# STM32L100C6U6 register map
File version: 1.0
Registers are 32-bit, access not given, reset 0x0 unless marked. A register's access mark holds for its fields unless they carry their own. Offsets are from the block's base; [hi:lo] are bit positions; {n}, {i} and the like mark numbered series.

## I2C1
Base 0x40005400
Same registers: I2C2 0x40005800
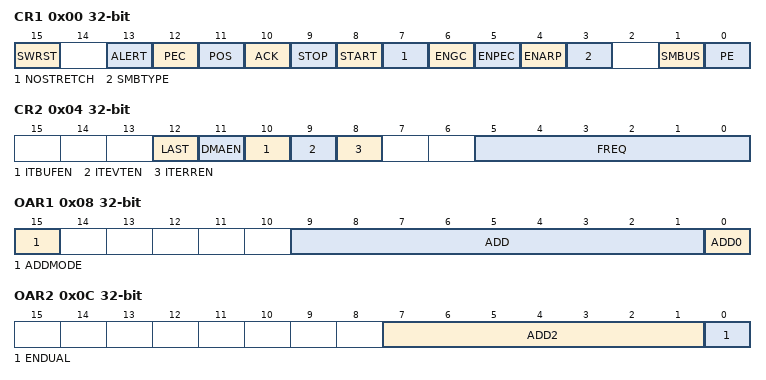
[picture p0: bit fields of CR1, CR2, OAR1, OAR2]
0x00 CR1
  [15] SWRST, [13] ALERT, [12] PEC, [11] POS, [10] ACK, [9] STOP, [8] START, [7] NOSTRETCH, [6] ENGC, [5] ENPEC, [4] ENARP, [3] SMBTYPE, [1] SMBUS, [0] PE
0x04 CR2
  [12] LAST, [11] DMAEN, [10] ITBUFEN, [9] ITEVTEN, [8] ITERREN, [5:0] FREQ
0x08 OAR1
  [15] ADDMODE, [9:1] ADD, [0] ADD0
0x0C OAR2
  [7:1] ADD2, [0] ENDUAL
0x10 DR
  [7:0] DR
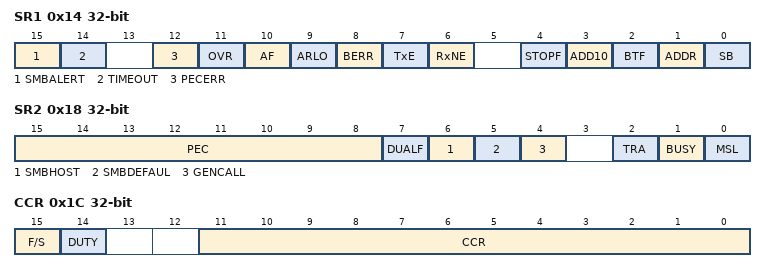
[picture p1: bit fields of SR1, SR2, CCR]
0x14 SR1
  [15] SMBALERT, [14] TIMEOUT, [12] PECERR, [11] OVR, [10] AF, [9] ARLO, [8] BERR, [7] TxE, [6] RxNE, [4] STOPF, [3] ADD10, [2] BTF, [1] ADDR, [0] SB
0x18 SR2
  [15:8] PEC, [7] DUALF, [6] SMBHOST, [5] SMBDEFAUL, [4] GENCALL, [2] TRA, [1] BUSY, [0] MSL
0x1C CCR
  [15] F/S, [14] DUTY, [11:0] CCR
0x20 TRISE
  [5:0] TRISE

## USBFS
Base 0x40005C00
Same registers: USBFSSRAM512 0x40006000
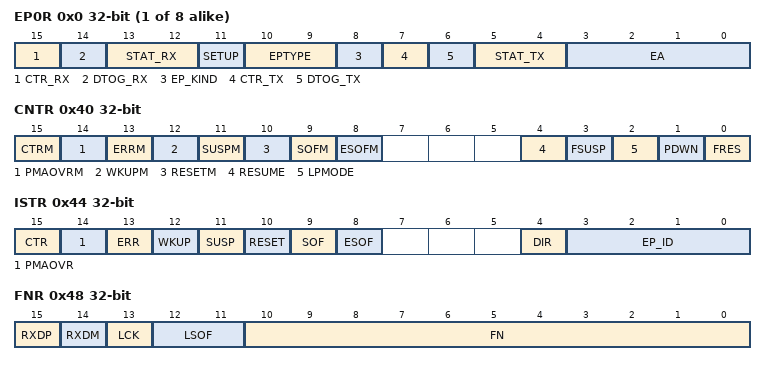
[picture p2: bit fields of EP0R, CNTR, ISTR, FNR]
{0x0+4i} EP{i}R (i=0..7)
  [15] CTR_RX, [14] DTOG_RX, [13:12] STAT_RX, [11] SETUP, [10:9] EPTYPE, [8] EP_KIND, [7] CTR_TX, [6] DTOG_TX, [5:4] STAT_TX, [3:0] EA
0x40 CNTR
  [15] CTRM, [14] PMAOVRM, [13] ERRM, [12] WKUPM, [11] SUSPM, [10] RESETM, [9] SOFM, [8] ESOFM, [4] RESUME, [3] FSUSP, [2] LPMODE, [1] PDWN, [0] FRES
0x44 ISTR
  [15] CTR, [14] PMAOVR, [13] ERR, [12] WKUP, [11] SUSP, [10] RESET, [9] SOF, [8] ESOF, [4] DIR, [3:0] EP_ID
0x48 FNR
  [15] RXDP, [14] RXDM, [13] LCK, [12:11] LSOF, [10:0] FN
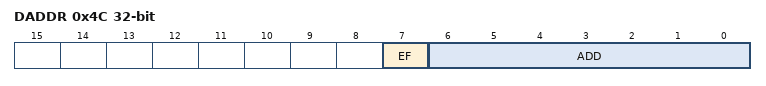
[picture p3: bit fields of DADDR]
0x4C DADDR
  [7] EF, [6:0] ADD
0x50 BTABLE
  [15:3] BTABLE

## PWR
Base 0x40007000
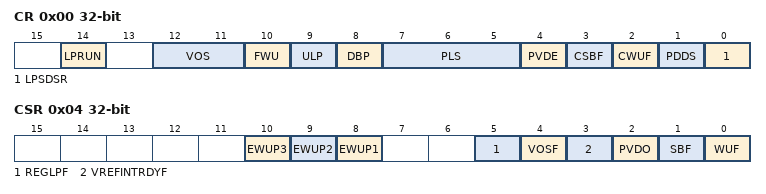
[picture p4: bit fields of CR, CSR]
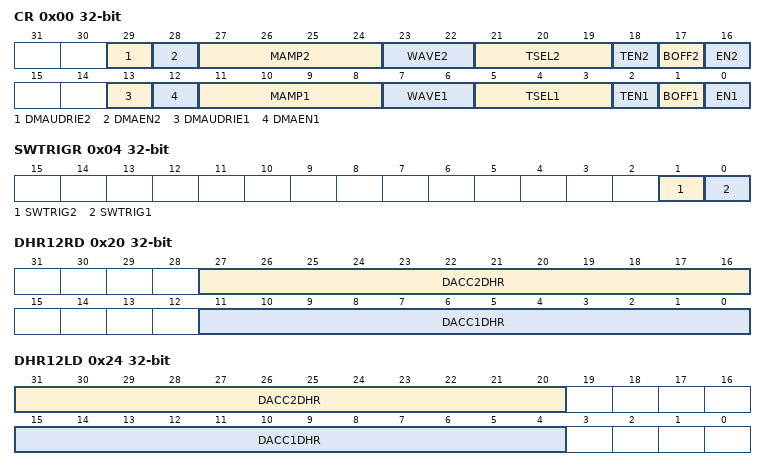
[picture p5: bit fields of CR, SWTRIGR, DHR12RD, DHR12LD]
0x00 CR
  [14] LPRUN, [12:11] VOS, [10] FWU, [9] ULP, [8] DBP, [7:5] PLS, [4] PVDE, [3] CSBF, [2] CWUF, [1] PDDS, [0] LPSDSR
0x04 CSR
  [10] EWUP3, [9] EWUP2, [8] EWUP1, [5] REGLPF, [4] VOSF, [3] VREFINTRDYF, [2] PVDO, [1] SBF, [0] WUF

## DAC
Base 0x40007400
0x00 CR
  [29] DMAUDRIE2, [28] DMAEN2, [27:24] MAMP2, [23:22] WAVE2, [21:19] TSEL2, [18] TEN2, [17] BOFF2, [16] EN2, [13] DMAUDRIE1, [12] DMAEN1, [11:8] MAMP1, [7:6] WAVE1, [5:3] TSEL1, [2] TEN1, [1] BOFF1, [0] EN1
0x04 SWTRIGR
  [1] SWTRIG2, [0] SWTRIG1
0x08 DHR12R1
  [11:0] DACC1DHR
0x0C DHR12L1
  [15:4] DACC1DHR
0x10 DHR8R1
  [7:0] DACC1DHR
0x14 DHR12R2
  [11:0] DACC2DHR
0x18 DHR12L2
  [15:4] DACC2DHR
0x1C DHR8R2
  [7:0] DACC2DHR
0x20 DHR12RD
  [27:16] DACC2DHR, [11:0] DACC1DHR
0x24 DHR12LD
  [31:20] DACC2DHR, [15:4] DACC1DHR
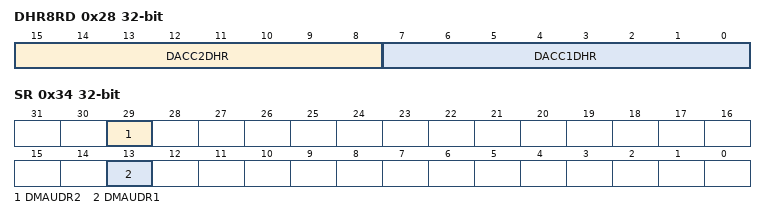
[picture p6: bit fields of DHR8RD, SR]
0x28 DHR8RD
  [15:8] DACC2DHR, [7:0] DACC1DHR
0x2C DOR1
  [11:0] DACC1DOR
0x30 DOR2
  [11:0] DACC2DOR
0x34 SR
  [29] DMAUDR2, [13] DMAUDR1

## COMP
Base 0x40007C00
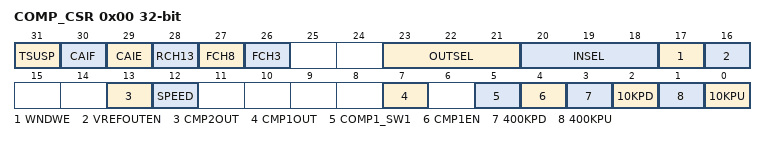
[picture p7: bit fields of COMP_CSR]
0x00 COMP_CSR
  [31] TSUSP, [30] CAIF, [29] CAIE, [28] RCH13, [27] FCH8, [26] FCH3, [23:21] OUTSEL, [20:18] INSEL, [17] WNDWE, [16] VREFOUTEN, [13] CMP2OUT, [12] SPEED, [7] CMP1OUT, [5] COMP1_SW1, [4] CMP1EN, [3] 400KPD, [2] 10KPD, [1] 400KPU, [0] 10KPU

## RI
Base 0x40007C04
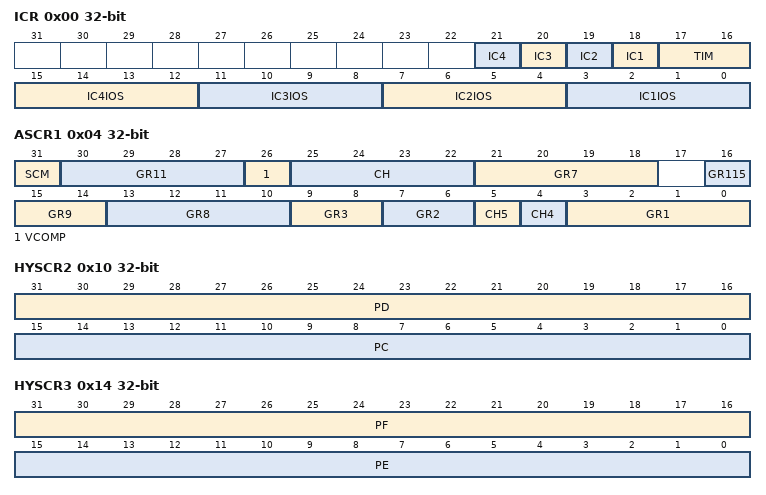
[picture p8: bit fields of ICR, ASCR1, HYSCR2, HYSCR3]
0x00 ICR
  [n+17] IC{n} (n=1..4), [17:16] TIM, [4n-1:4n-4] IC{n}IOS (n=1..4)
0x04 ASCR1
  [31] SCM, [30:27] GR11, [26] VCOMP, [25:22] CH, [21:18] GR7, [16] GR115, [15:14] GR9, [13:10] GR8, [9:8] GR3, [7:6] GR2, [5] CH5, [4] CH4, [3:0] GR1
0x08 ASCR2
  [26:24] GR7, [23:21] GR2, [20:19] GR9, [18:16] GR3, [11:9] GR4, [8:6] GR5, [28:4] GR6, [3:0] GR10
0x10 HYSCR2
  [31:16] PD, [15:0] PC
0x14 HYSCR3
  [31:16] PF, [15:0] PE
0x18 HYSCR4
  [15:0] PG
0x1C ASMR1
  [15:0] PA
0x20 CMR1
  [15:0] PA
0x24 CICR1
  [15:0] PA
0x28 ASMR2
  [15:0] PB
0x2C CMR2
  [15:0] PB
0x30 CICR2
  [15:0] PB
0x34 ASMR3
  [15:0] PC
0x38 CMR3
  [15:0] PC
0x3C CICR3
  [15:0] PC
0x40 ASMR4
  [15:0] PF
0x44 CMR4
  [15:0] PF
0x48 CICR4
  [15:0] PF
0x4C ASMR5
  [15:0] PG
0x50 CMR5
  [15:0] PG
0x54 CICR5
  [15:0] PG
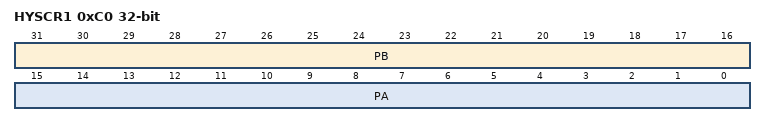
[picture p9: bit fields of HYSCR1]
0xC0 HYSCR1
  [31:16] PB, [15:0] PA

## OPAMP
Base 0x40007C5C
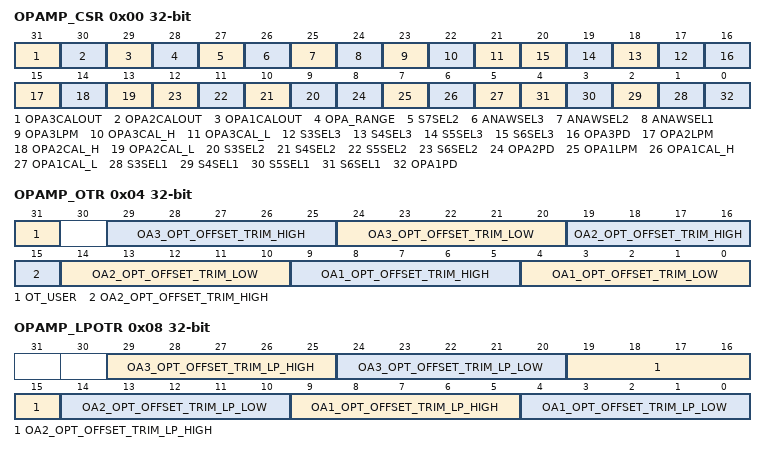
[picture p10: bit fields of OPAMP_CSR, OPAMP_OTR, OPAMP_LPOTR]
0x00 OPAMP_CSR
  [31] OPA3CALOUT, [30] OPA2CALOUT, [29] OPA1CALOUT, [28] OPA_RANGE, [27] S7SEL2, [26] ANAWSEL3, [25] ANAWSEL2, [24] ANAWSEL1, [23] OPA3LPM, [22] OPA3CAL_H, [21] OPA3CAL_L, [n+14] S{n}SEL3 (n=3..6), [16] OPA3PD, [15] OPA2LPM, [14] OPA2CAL_H, [13] OPA2CAL_L, [n+6] S{n}SEL2 (n=3..6), [8] OPA2PD, [7] OPA1LPM, [6] OPA1CAL_H, [5] OPA1CAL_L, [n-2] S{n}SEL1 (n=3..6), [0] OPA1PD
0x04 OPAMP_OTR
  [31] OT_USER, [29:25] OA3_OPT_OFFSET_TRIM_HIGH, [24:20] OA3_OPT_OFFSET_TRIM_LOW, [19:15] OA2_OPT_OFFSET_TRIM_HIGH, [14:10] OA2_OPT_OFFSET_TRIM_LOW, [9:5] OA1_OPT_OFFSET_TRIM_HIGH, [4:0] OA1_OPT_OFFSET_TRIM_LOW
0x08 OPAMP_LPOTR
  [29:25] OA3_OPT_OFFSET_TRIM_LP_HIGH, [24:20] OA3_OPT_OFFSET_TRIM_LP_LOW, [19:15] OA2_OPT_OFFSET_TRIM_LP_HIGH, [14:10] OA2_OPT_OFFSET_TRIM_LP_LOW, [9:5] OA1_OPT_OFFSET_TRIM_LP_HIGH, [4:0] OA1_OPT_OFFSET_TRIM_LP_LOW
